# M051AN_v1 register map
File version: 1.0
Registers are 32-bit, read-write, reset 0x0 unless marked. A register's access mark holds for its fields unless they carry their own. Offsets are from the block's base; [hi:lo] are bit positions; lines under a group give offsets from that group; {n}, {i} and the like mark numbered series; 'fields as' and 'values as' point back to an identical list.

## PWMA — PWM Register Map
Base 0x40040000
Same registers: PWMB 0x40140000
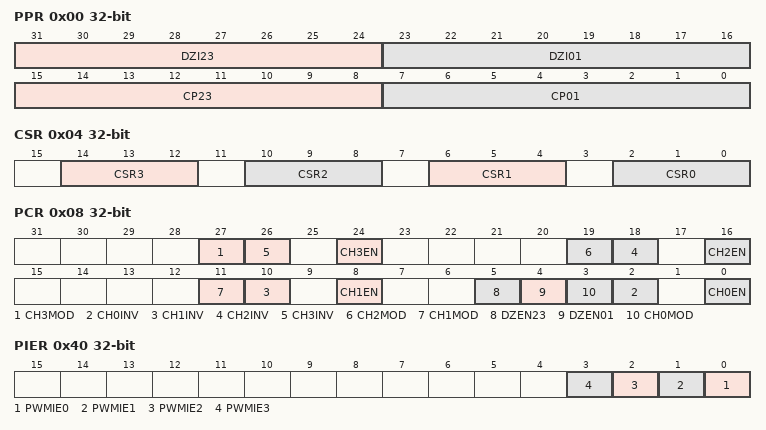
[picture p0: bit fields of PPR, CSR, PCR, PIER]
0x00 PPR — PWM Pre-scale Register
  [31:24] DZI23 — Dead zone interval register for pair of channel2 and channel3 (PWM2 and PWM3 pair for PWM group A, PWM6 and PWM7 pair for PWM group B). These 8 bits determine dead zone length. The unit time of dead zone length is received from corresponding CSR bits.
  [23:16] DZI01 — Dead zone interval register for pair of channel 0 and channel 1 (PWM0 and PWM1 pair for PWM group A, PWM4 and PWM5 pair for PWM group B). These 8 bits determine dead zone length. The unit time of dead zone length is received from corresponding CSR bits.
  [15:8] CP23 — Clock prescaler 2 (PWM counter 2/ 3 for group A and PWM counter 6/ 7 for group B). Clock input is divided by (CP23 + 1) before it is fed to the corresponding PWM counter
  [7:0] CP01 — Clock prescaler 0 (PWM counter 0/1 for group A and PWM counter 4/ 5 for group B). Clock input is divided by (CP01 + 1) before it is fed to the corresponding PWM counter
0x04 CSR — PWM Clock Select Register
  [14:12] CSR3 — Timer 3 Clock Source Selection (PWM timer 3 for group A and PWM timer 7 for group B)
  [10:8] CSR2 — Timer 2 Clock Source Selection (PWM timer 2 for group A and PWM timer 6 for group B). Select clock input for PWM timer. (Table is the same as CSR3)
  [6:4] CSR1 — Timer 1 Clock Source Selection (PWM timer 1 for group A and PWM timer 5 for group B). Select clock input for PWM timer. (Table is the same as CSR3)
  [2:0] CSR0 — Timer 0 Clock Source Selection (PWM timer 0 for group A and PWM timer 4 for group B). Select clock input for PWM timer. (Table is the same as CSR3)
0x08 PCR — PWM Control Register
  [27] CH3MOD — PWM-Timer 3 Auto-reload/One-Shot Mode (PWM timer 3 for group A and PWM timer 7 for group B). Note: If there is a rising transition at this bit, it will cause CNR3 and CMR3 be clear.
    0=One-Shot Mode; 1=Auto-reload Mode
  [8n+2] CH{n}INV (n=0..3) — PWM-Timer {n} Output Inverter ON/OFF (PWM timer {n} for group A and PWM timer {n+4} for group B)
    0=Inverter OFF; 1=Inverter ON
  [8n] CH{n}EN (n=0..3) — PWM-Timer {n} Enable/Disable Start Run (PWM timer {n} for group A and PWM timer {n+4} for group B)
    0=Stop corresponding PWM-Timer Running; 1=Enable corresponding PWM-Timer Start Run
  [19] CH2MOD — PWM-Timer 2 Auto-reload/One-Shot Mode (PWM timer 2 for group A and PWM timer 6 for group B). Note: If there is a rising transition at this bit, it will cause CNR2 and CMR2 be clear.
    0=One-Shot Mode; 1=Auto-reload Mode
  [11] CH1MOD — PWM-Timer 1 Auto-reload/One-Shot Mode (PWM timer 1 for group A and PWM timer 5 for group B). Note: If there is a rising transition at this bit, it will cause CNR1 and CMR1 be clear.
    0=One-Shot Mode; 1=Auto-load Mode
  [5] DZEN23 — Dead-Zone 2 Generator Enable/Disable (PWM2 and PWM3 pair for PWM group A, PWM6 and PWM7 pair for PWM group B). Note: When Dead-Zone Generator is enabled, the pair of PWM2 and PWM3 becomes a complementary pair for PWM group A and the pair of PWM6 and PWM7 becomes a complementary pair for PWM group B.
    0=Disable; 1=Enable
  [4] DZEN01 — Dead-Zone 0 Generator Enable/Disable (PWM0 and PWM1 pair for PWM group A, PWM4 and PWM5 pair for PWM group B). Note: When Dead-Zone Generator is enabled, the pair of PWM0 and PWM1 becomes a complementary pair for PWM group A and the pair of PWM4 and PWM5 becomes a complementary pair for PWM group B.
    0=Disable; 1=Enable
  [3] CH0MOD — PWM-Timer 0 Auto-reload/One-Shot Mode (PWM timer 0 for group A and PWM timer 4 for group B). Note: If there is a rising transition at this bit, it will cause CNR0 and CMR0 be clear.
    0=One-Shot Mode; 1=Auto-reload Mode
{0xC+0xC*i} CNR{i} (i=0..3) — PWM Counter Register {i}
  [15:0] CNRx — PWM Counter/Timer Loaded Value. CNR determines the PWM period. Note: Any write to CNR will take effect in next PWM cycle.
{0x10+0xC*i} CMR{i} (i=0..3) — PWM Comparator Register {i}
  [15:0] CMRx — PWM Comparator Register. CMR determines the PWM duty. Note: Any write to CMR will take effect in next PWM cycle.
{0x14+0xC*i} PDR{i} ro (i=0..3) — PWM Data Register {i}
  [15:0] PDRx — PWM Data Register. User can monitor PDR to know the current value in 16-bit down counter.
0x40 PIER — PWM Interrupt Enable Register
  [all] fields
    0=Disable; 1=Enable
  [n] PWMIE{n} (n=0..3) — PWM channel {n} Interrupt Enable
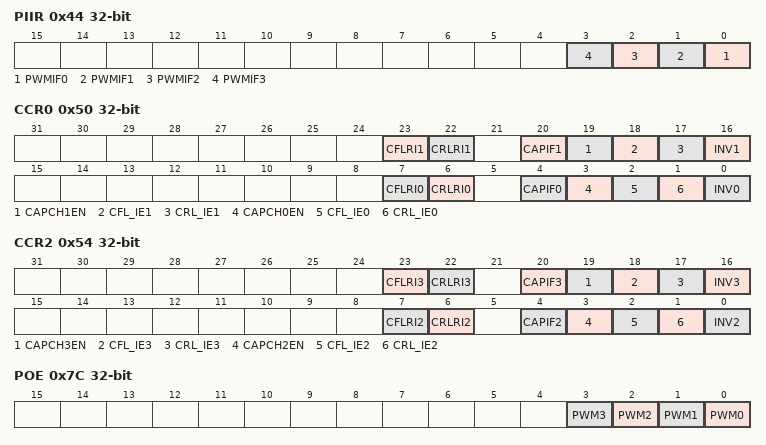
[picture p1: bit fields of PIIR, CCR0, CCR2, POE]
0x44 PIIR — PWM Interrupt Indication Register
  [n] PWMIF{n} (n=0..3) — PWM channel {n} Interrupt Status. Flag is set by hardware when PWM{n} down counter reaches zero, software can clear this bit by writing a one to it.
0x50 CCR0 — PWM Capture Control Register 0
  [23] CFLRI1 — CFLR1 Latched Indicator Bit. When PWM group input channel 1 has a falling transition, CFLR1 was latched with the value of PWM down-counter and this bit is set by hardware. Clear this bit by writing a one to it.
  [22] CRLRI1 — CRLR1 Latched Indicator Bit. When PWM group input channel 1 has a rising transition, CRLR1 was latched with the value of PWM down-counter and this bit is set by hardware. Clear this bit by writing a one to it.
  [20] CAPIF1 — Capture1 Interrupt Indication Flag
  [19] CAPCH1EN — Capture PWM Group Channel 1 transition Enable/Disable. When Enable, Capture latched the PMW-counter and saved to CRLR (Rising latch) and CFLR (Falling latch). When Disable, Capture does not update CRLR and CFLR, and disable PWM group channel 1 Interrupt.
    0=Disable capture function on PWM group channel 1; 1=Enable capture function on PWM group channel 1
  [18] CFL_IE1 — PWM Group Channel 1 Falling Latch Interrupt Enable. When Enable, if Capture detects PWM group channel 1 has falling transition, Capture issues an Interrupt.
    0=Disable falling latch interrupt; 1=Enable falling latch interrupt
  [17] CRL_IE1 — PWM Group Channel 1 Rising Latch Interrupt Enable. When Enable, if Capture detects PWM group channel 1 has rising transition, Capture issues an Interrupt.
    0=Disable rising latch interrupt; 1=Enable rising latch interrupt
  [16] INV1 — PWM Group Channel 1 Inverter ON/OFF
    0=Inverter OFF; 1=Inverter ON. Reverse the input signal from GPIO before fed to Capture timer
  [7] CFLRI0 — CFLR0 Latched Indicator Bit. When PWM group input channel 0 has a falling transition, CFLR0 was latched with the value of PWM down-counter and this bit is set by hardware. Clear this bit by writing a one to it.
  [6] CRLRI0 — CRLR0 Latched Indicator Bit. When PWM group input channel 0 has a rising transition, CRLR0 was latched with the value of PWM down-counter and this bit is set by hardware. Clear this bit by writing a one to it.
  [4] CAPIF0 — Capture0 Interrupt Indication Flag
  [3] CAPCH0EN — Capture Channel 0 transition Enable/Disable. When Enable, Capture latched the PWM-counter value and saved to CRLR (Rising latch) and CFLR (Falling latch). When Disable, Capture does not update CRLR and CFLR, and disable PWM group channel 0 Interrupt.
    0=Disable capture function on PWM group channel 0; 1=Enable capture function on PWM group channel 0
  [2] CFL_IE0 — PWM Group Channel 0 Falling Latch Interrupt Enable ON/OFF. When Enable, if Capture detects PWM group channel 0 has falling transition, Capture issues an Interrupt.
    values as CFL_IE1
  [1] CRL_IE0 — PWM Group Channel 0 Rising Latch Interrupt Enable ON/OFF. When Enable, if Capture detects PWM group channel 0 has rising transition, Capture issues an Interrupt.
    values as CRL_IE1
  [0] INV0 — PWM Group Channel 0 Inverter ON/OFF
    values as INV1
0x54 CCR2 — PWM Capture Control Register 2
  [23] CFLRI3 — CFLR3 Latched Indicator Bit. When PWM group input channel 3 has a falling transition, CFLR3 was latched with the value of PWM down-counter and this bit is set by hardware. Write 1 to clear this bit to zero.
  [22] CRLRI3 — CRLR3 Latched Indicator Bit. When PWM group input channel 3 has a rising transition, CRLR3 was latched with the value of PWM down-counter and this bit is set by hardware. Write 1 to clear this bit to zero.
  [20] CAPIF3 — Capture3 Interrupt Indication Flag. Write 1 to clear this bit to zero.
  [19] CAPCH3EN — Capture Channel 3 transition Enable/Disable. When Enable, Capture latched the PMW-counter and saved to CRLR (Rising latch) and CFLR (Falling latch). When Disable, Capture does not update CRLR and CFLR, and disable PWM group channel 3 Interrupt.
    0=Disable capture function on PWM group channel 3; 1=Enable capture function on PWM group channel 3
  [18] CFL_IE3 — PWM Group Channel 3 Falling Latch Interrupt Enable. When Enable, if Capture detects PWM group channel 3 has falling transition, Capture issues an Interrupt.
    values as CCR0.CFL_IE1
  [17] CRL_IE3 — PWM Group Channel 3 Rising Latch Interrupt Enable. When Enable, if Capture detects PWM group channel 3 has rising transition, Capture issues an Interrupt.
    values as CCR0.CRL_IE1
  [16] INV3 — PWM Group Channel 3 Inverter ON/OFF
    values as CCR0.INV1
  [7] CFLRI2 — CFLR2 Latched Indicator Bit. When PWM group input channel 2 has a falling transition, CFLR2 was latched with the value of PWM down-counter and this bit is set by hardware. Note: Write 1 to clear this bit to zero.
  [6] CRLRI2 — CRLR2 Latched Indicator Bit. When PWM group input channel 2 has a rising transition, CRLR2 was latched with the value of PWM down-counter and this bit is set by hardware. Note: Write 1 to clear this bit to zero.
  [4] CAPIF2 — Capture2 Interrupt Indication Flag. Note: Write 1 to clear this bit to zero.
  [3] CAPCH2EN — Capture Channel 2 transition Enable/Disable. When Enable, Capture latched the PWM-counter value and saved to CRLR (Rising latch) and CFLR (Falling latch). When Disable, Capture does not update CRLR and CFLR, and disable PWM group channel 2 Interrupt.
    0=Disable capture function on PWM group channel 2; 1=Enable capture function on PWM group channel 2
  [2] CFL_IE2 — PWM Group Channel 2 Falling Latch Interrupt Enable ON/OFF. When Enable, if Capture detects PWM group channel 2 has falling transition, Capture issues an Interrupt.
    values as CCR0.CFL_IE1
  [1] CRL_IE2 — PWM Group Channel 2 Rising Latch Interrupt Enable ON/OFF. When Enable, if Capture detects PWM group channel 2 has rising transition, Capture issues an Interrupt.
    values as CCR0.CRL_IE1
  [0] INV2 — PWM Group Channel 2 Inverter ON/OFF
    values as CCR0.INV1
{0x58+8i} CRLR{i} ro (i=0..3) — PWM Capture Rising Latch Register (Channel {i})
  [15:0] CRLRx — Capture Rising Latch Register. Latch the PWM counter when Channel 0/1/2/3 has rising transition.
{0x5C+8i} CFLR{i} ro (i=0..3) — PWM Capture Falling Latch Register (Channel {i})
  [15:0] CFLRx — Capture Falling Latch Register. Latch the PWM counter when Channel 01/2/3 has Falling transition.
0x78 CAPENR — PWM Capture Input 0~3 Enable Register
  [3:0] CAPENR — Capture Input Enable Register. There are four capture inputs from pad. Bit0~Bit3 are used to control each inputs ON or OFF. CAPENR. Bit 3210 for PWM group A. Bit xxx1 ( Capture channel 0 is from P2.0. Bit xx1x ( Capture channel 1 is from P2.1. Bit x1xx ( Capture channel 2 is from P2.2. Bit 1xxx ( Capture channel 3 is from P2.3. Bit 3210 for PWM group B. Bit xxx1 ( Capture channel 0 is from P2.4. Bit xx1x ( Capture channel 1 is from P2.5. Bit x1xx ( Capture channel 2 is from P2.6. Bit 1xxx ( Capture channel 3 is from P2.7
    0=OFF (PWMx multi-function pin input does not affect input capture function.); 1=ON (PWMx multi-function pin input will affect its input capture function.)
0x7C POE — PWM Output Enable Register for Channel 0~3
  [n] PWM{n} (n=0..3) — PWM Channel {n} Output Enable Register. Note: The corresponding GPIO pin also must be switched to PWM function
    0=Disable PWM channel {n} output to pin; 1=Enable PWM channel {n} output to pin
